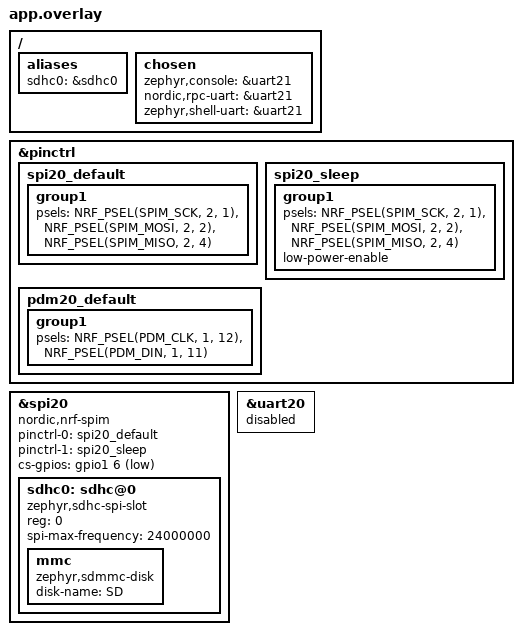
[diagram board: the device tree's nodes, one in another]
/* SD Card configuration for XIAO Expansion Base
 * Using SPI bit-bang instead of hardware SPI
 * Pins: D8=SCK, D9=MISO, D10=MOSI, D2=CS
 */

/ {
	

	aliases {
		sdhc0 = &sdhc0;
		/delete-property/ dmic0;
	};

	chosen {
		zephyr,console = &uart21;
		nordic,rpc-uart = &uart21;
		zephyr,shell-uart = &uart21;
	};

	

};

&pinctrl {
	spi20_default: spi20_default {
		group1 {
			psels = <NRF_PSEL(SPIM_SCK, 2, 1)>,
					<NRF_PSEL(SPIM_MOSI, 2, 2)>,
					<NRF_PSEL(SPIM_MISO, 2, 4)>;
		};
	};

	spi20_sleep: spi20_sleep {
		group1 {
			psels = <NRF_PSEL(SPIM_SCK, 2, 1)>,
					<NRF_PSEL(SPIM_MOSI, 2, 2)>,
					<NRF_PSEL(SPIM_MISO, 2, 4)>;
			low-power-enable;
		};
	};

	pdm20_default: pdm20_default {
		group1 {
			psels = <NRF_PSEL(PDM_CLK, 1, 12)>,
					<NRF_PSEL(PDM_DIN, 1, 11)>;
		};
	};
};

&spi20 {
	compatible = "nordic,nrf-spim";
	pinctrl-names = "default", "sleep";
	pinctrl-0 = <&spi20_default>;
	pinctrl-1 = <&spi20_sleep>;
	status = "okay";

	cs-gpios = <&gpio1 6 (GPIO_ACTIVE_LOW | GPIO_PULL_UP)>;
	sdhc0: sdhc@0 {
		
			compatible = "zephyr,sdhc-spi-slot";
			reg = <0>;
			status = "okay";
			mmc {
				compatible = "zephyr,sdmmc-disk";
				disk-name = "SD";
				status = "okay";
			};
			spi-max-frequency = <24000000>;
		};
};

&uart20 {
	status = "disabled";
};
